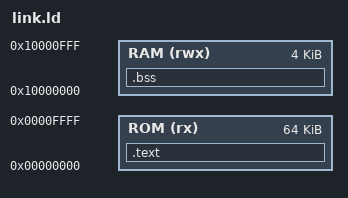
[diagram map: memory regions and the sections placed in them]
/* Linker script for teaching SoC — code and strings in ROM */
MEMORY
{
    ROM (rx)  : ORIGIN = 0x00000000, LENGTH = 64K
    RAM (rwx) : ORIGIN = 0x10000000, LENGTH = 4K
}

SECTIONS
{
    .text : {
        *(.text.start)
        *(.text*)
        *(.rodata*)
        *(.srodata*)
    } > ROM

    .bss (NOLOAD) : {
        *(.bss*)
        *(.sbss*)
        *(COMMON)
    } > RAM

    _stack_top = ORIGIN(RAM) + LENGTH(RAM);
}
